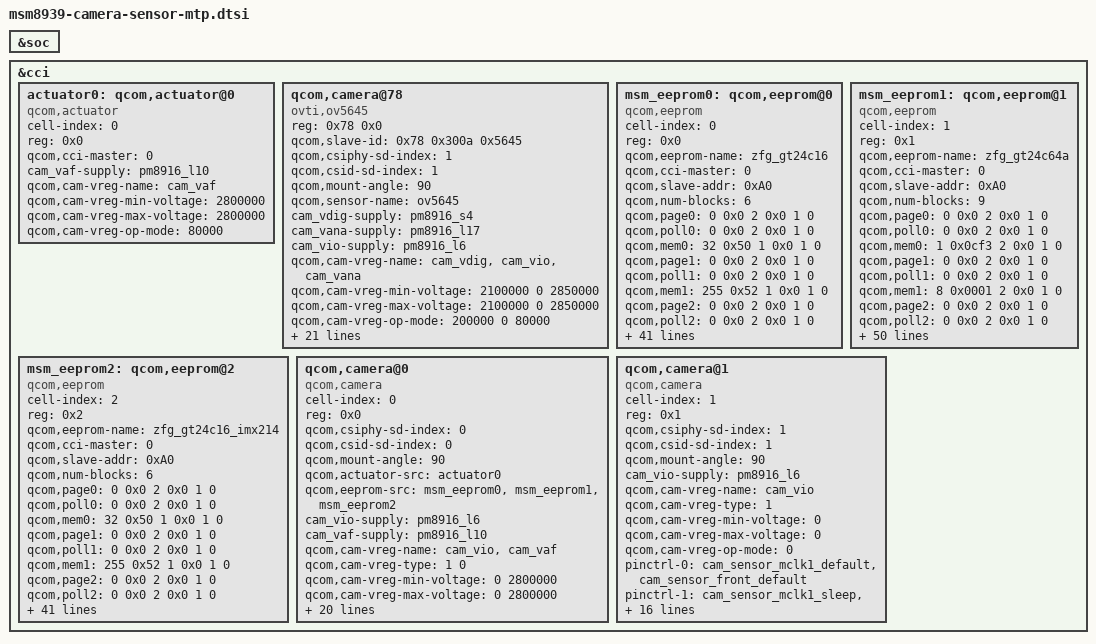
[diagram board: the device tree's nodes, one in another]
/*
 * Copyright (c) 2014-2015, The Linux Foundation. All rights reserved.
 *
 * This program is free software; you can redistribute it and/or modify
 * it under the terms of the GNU General Public License version 2 and
 * only version 2 as published by the Free Software Foundation.
 *
 * This program is distributed in the hope that it will be useful,
 * but WITHOUT ANY WARRANTY; without even the implied warranty of
 * MERCHANTABILITY or FITNESS FOR A PARTICULAR PURPOSE.  See the
 * GNU General Public License for more details.
 */

&soc {
};

&cci {

	actuator0: qcom,actuator@0 {
		cell-index = <0>;
		reg = <0x0>;
		compatible = "qcom,actuator";
		qcom,cci-master = <0>;
		cam_vaf-supply = <&pm8916_l10>;
		qcom,cam-vreg-name = "cam_vaf";
		qcom,cam-vreg-min-voltage = <2800000>;
		qcom,cam-vreg-max-voltage = <2800000>;
		qcom,cam-vreg-op-mode = <80000>;
	};

	qcom,camera@78 {
		compatible = "ovti,ov5645";
		reg = <0x78 0x0>;
		qcom,slave-id = <0x78 0x300a 0x5645>;
		qcom,csiphy-sd-index = <1>;
		qcom,csid-sd-index = <1>;
		qcom,mount-angle = <90>;
		qcom,sensor-name = "ov5645";
		cam_vdig-supply = <&pm8916_s4>;
		cam_vana-supply = <&pm8916_l17>;
		cam_vio-supply = <&pm8916_l6>;
		qcom,cam-vreg-name = "cam_vdig", "cam_vio", "cam_vana";
		qcom,cam-vreg-min-voltage = <2100000 0 2850000>;
		qcom,cam-vreg-max-voltage = <2100000 0 2850000>;
		qcom,cam-vreg-op-mode = <200000 0 80000>;
		pinctrl-names = "cam_default", "cam_suspend";
		pinctrl-0 = <&cam_sensor_mclk1_default
				&cam_sensor_front_default>;
		pinctrl-1 = <&cam_sensor_mclk1_sleep &cam_sensor_front_sleep>;
		gpios = <&msm_gpio 27 0>,
			<&msm_gpio 28 0>,
			<&msm_gpio 33 0>;
		qcom,gpio-reset = <1>;
		qcom,gpio-standby = <2>;
		qcom,gpio-req-tbl-num = <0 1 2>;
		qcom,gpio-req-tbl-flags = <1 0 0>;
		qcom,gpio-req-tbl-label = "CAMIF_MCLK",
					"CAM_RESET",
					"CAM_STANDBY";
		qcom,gpio-set-tbl-num = <1 1>;
		qcom,gpio-set-tbl-flags = <0 2>;
		qcom,gpio-set-tbl-delay = <1000 4000>;
		qcom,csi-lane-assign = <0x4320>;
		qcom,csi-lane-mask = <0x3>;
		qcom,sensor-position = <1>;
		qcom,sensor-mode = <0>;
		qcom,cci-master = <0>;
		clocks = <&clock_gcc clk_mclk1_clk_src>,
				<&clock_gcc clk_gcc_camss_mclk1_clk>;
		clock-names = "cam_src_clk", "cam_clk";
	};

 msm_eeprom0: qcom,eeprom@0 {
		cell-index = <0>;
		reg = <0x0>;
		qcom,eeprom-name = "zfg_gt24c16";
		compatible = "qcom,eeprom";
		qcom,cci-master = <0>;
			
		qcom,slave-addr = <0xA0>;		
		qcom,num-blocks = <6>;
		
		qcom,page0 = <0 0x0 2 0x0 1 0>;
		qcom,poll0 = <0 0x0 2 0x0 1 0>;
		qcom,mem0 = <32 0x50 1 0x0 1 0>;  

		qcom,page1 = <0 0x0 2 0x0 1 0>;
		qcom,poll1 = <0 0x0 2 0x0 1 0>;
		qcom,mem1 = <255 0x52 1 0x0 1 0>;  

		qcom,page2 = <0 0x0 2 0x0 1 0>;
		qcom,poll2 = <0 0x0 2 0x0 1 0>;
		qcom,mem2 = <255 0x53 1 0x0 1 0>;  
		
		qcom,page3 = <0 0x0 2 0x0 1 0>;
		qcom,poll3 = <0 0x0 2 0x0 1 0>;
		qcom,mem3 = <255 0x54 1 0x0 1 0>;  
		
		qcom,page4 = <0 0x0 2 0x0 1 0>;
		qcom,poll4 = <0 0x0 2 0x0 1 0>;
		qcom,mem4 = <255 0x55 1 0x0 1 0>;  
		
		qcom,page5 = <0 0x0 2 0x0 1 0>;
		qcom,poll5 = <0 0x0 2 0x0 1 0>;
		qcom,mem5 = <86 0x56 1 0x0 1 0>; 
		
		cam_vio-supply = <&pm8916_l6>; 
	    qcom,cam-vreg-name =  "cam_vio";
		qcom,cam-vreg-min-voltage = <0 >;
		qcom,cam-vreg-max-voltage = <0>;
		qcom,cam-vreg-op-mode = <0>;
		pinctrl-names = "cam_default", "cam_suspend";
		pinctrl-0 = <&cam_sensor_mclk0_default &cam_sensor_rear_default>;
		pinctrl-1 = <&cam_sensor_mclk0_sleep &cam_sensor_rear_sleep>;
		qcom,gpio-no-mux = <0>;
		gpios = <&msm_gpio 26 0>,
			<&msm_gpio 35 0>,
			<&msm_gpio 34 0>,
			<&msm_gpio 109 0>,
			<&msm_gpio 69 0>;
		qcom,gpio-reset = <1>;
		qcom,gpio-standby = <2>;
		qcom,gpio-vdig = <3>;
		qcom,gpio-vana = <4>;
		qcom,gpio-req-tbl-num = <0 1 2 3 4>;
		qcom,gpio-req-tbl-flags = <1 0 0 0 0>;
		qcom,gpio-req-tbl-label = "CAMIF_MCLK0",
			"CAM_RESET0",
			"CAM_STANDBY0",
				"CAM_VDIG",
			"CAM_VANA";
		qcom,gpio-set-tbl-num = <1 1>;
		qcom,gpio-set-tbl-flags = <0 2>;
		qcom,gpio-set-tbl-delay = <1000 4000>;
		qcom,cam-power-seq-type =  "sensor_vreg","sensor_gpio", "sensor_clk";
		qcom,cam-power-seq-val = "cam_vio", "sensor_gpio_vaf", "sensor_cam_mclk";
		qcom,cam-power-seq-cfg-val = <1 1 24000000>;
		qcom,cam-power-seq-delay = <10 30 5>;
		clocks = <&clock_gcc clk_mclk0_clk_src>,
				<&clock_gcc clk_gcc_camss_mclk0_clk>;
		clock-names = "cam_src_clk", "cam_clk";
	};

    msm_eeprom1: qcom,eeprom@1 {
		cell-index = <1>;
		reg = <0x1>;
		qcom,eeprom-name = "zfg_gt24c64a";
		compatible = "qcom,eeprom";
		qcom,cci-master = <0>;
			
		qcom,slave-addr = <0xA0>;		
		qcom,num-blocks = <9>;
		
		qcom,page0 = <0 0x0 2 0x0 1 0>;
		qcom,poll0 = <0 0x0 2 0x0 1 0>;
		qcom,mem0 = <1 0x0cf3 2 0x0 1 0>;  //AWB flag

		qcom,page1 = <0 0x0 2 0x0 1 0>;
		qcom,poll1 = <0 0x0 2 0x0 1 0>;
		qcom,mem1 = <8 0x0001 2 0x0 1 0>;  //Module info(include checksum)

		qcom,page2 = <0 0x0 2 0x0 1 0>;
		qcom,poll2 = <0 0x0 2 0x0 1 0>;
		qcom,mem2 = <13 0x0CF4 2 0x0 1 0>;  //AWB(include checksum)
		
		qcom,page3 = <0 0x0 2 0x0 1 0>;
		qcom,poll3 = <0 0x0 2 0x0 1 0>;
		qcom,mem3 = <1770 0x0D01 2 0x0 1 0>;  //LSC(include flag and checksum)
		
		qcom,page4 = <0 0x0 2 0x0 1 0>;
		qcom,poll4 = <0 0x0 2 0x0 1 0>;
		qcom,mem4 = <8 0x0CE6 2 0x0 1 0>;  //AF(include flag and checksum)
		
		qcom,page5 = <0 0x0 2 0x0 1 0>;
		qcom,poll5 = <0 0x0 2 0x0 1 0>;
		qcom,mem5 = <7 0x13EB 2 0x0 1 0>;  //PD GAIN(include flag)
		
		qcom,page6 = <0 0x0 2 0x0 1 0>;
		qcom,poll6 = <0 0x0 2 0x0 1 0>;
		qcom,mem6 = <262 0x13F2 2 0x0 1 0>;  //PD LEFT GAIN MAP
		
		qcom,page7 = <0 0x0 2 0x0 1 0>;
		qcom,poll7 = <0 0x0 2 0x0 1 0>;
		qcom,mem7 = <263 0x14F8 2 0x0 1 0>;  //PD RIGHT GAIN MAP(include checksum)
		
		qcom,page8 = <0 0x0 2 0x0 1 0>;
		qcom,poll8 = <0 0x0 2 0x0 1 0>;
		qcom,mem8 = <3 0x17F3 2 0x0 1 0>;  //PD CC(include flag)
		
		cam_vio-supply = <&pm8916_l6>; 
	        qcom,cam-vreg-name =  "cam_vio";
		qcom,cam-vreg-min-voltage = <0 >;
		qcom,cam-vreg-max-voltage = <0>;
		qcom,cam-vreg-op-mode = <0>;
		pinctrl-names = "cam_default", "cam_suspend";
		pinctrl-0 = <&cam_sensor_mclk0_default &cam_sensor_rear_default>;
		pinctrl-1 = <&cam_sensor_mclk0_sleep &cam_sensor_rear_sleep>;
		qcom,gpio-no-mux = <0>;
		gpios = <&msm_gpio 26 0>,
			<&msm_gpio 35 0>,
			<&msm_gpio 34 0>,
			<&msm_gpio 109 0>,
			<&msm_gpio 69 0>;
		qcom,gpio-reset = <1>;
		qcom,gpio-standby = <2>;
		qcom,gpio-vdig = <3>;
		qcom,gpio-vana = <4>;
		qcom,gpio-req-tbl-num = <0 1 2 3 4>;
		qcom,gpio-req-tbl-flags = <1 0 0 0 0>;
		qcom,gpio-req-tbl-label = "CAMIF_MCLK0",
			"CAM_RESET0",
			"CAM_STANDBY0",
				"CAM_VDIG",
			"CAM_VANA";
		qcom,gpio-set-tbl-num = <1 1>;
		qcom,gpio-set-tbl-flags = <0 2>;
		qcom,gpio-set-tbl-delay = <1000 4000>;
		qcom,cam-power-seq-type =  "sensor_vreg","sensor_gpio", "sensor_clk";
		qcom,cam-power-seq-val = "cam_vio", "sensor_gpio_vaf", "sensor_cam_mclk";
		qcom,cam-power-seq-cfg-val = <1 1 24000000>;
		qcom,cam-power-seq-delay = <10 30 5>;
		clocks = <&clock_gcc clk_mclk0_clk_src>,
				<&clock_gcc clk_gcc_camss_mclk0_clk>;
		clock-names = "cam_src_clk", "cam_clk";
	};
	
    msm_eeprom2: qcom,eeprom@2 {
		cell-index = <2>;
		reg = <0x2>;
		qcom,eeprom-name = "zfg_gt24c16_imx214";
		compatible = "qcom,eeprom";
		qcom,cci-master = <0>;
			
		qcom,slave-addr = <0xA0>;		
		qcom,num-blocks = <6>;
		
		qcom,page0 = <0 0x0 2 0x0 1 0>;
		qcom,poll0 = <0 0x0 2 0x0 1 0>;
		qcom,mem0 = <32 0x50 1 0x0 1 0>;  

		qcom,page1 = <0 0x0 2 0x0 1 0>;
		qcom,poll1 = <0 0x0 2 0x0 1 0>;
		qcom,mem1 = <255 0x52 1 0x0 1 0>;  

		qcom,page2 = <0 0x0 2 0x0 1 0>;
		qcom,poll2 = <0 0x0 2 0x0 1 0>;
		qcom,mem2 = <255 0x53 1 0x0 1 0>;  
		
		qcom,page3 = <0 0x0 2 0x0 1 0>;
		qcom,poll3 = <0 0x0 2 0x0 1 0>;
		qcom,mem3 = <255 0x54 1 0x0 1 0>;  
		
		qcom,page4 = <0 0x0 2 0x0 1 0>;
		qcom,poll4 = <0 0x0 2 0x0 1 0>;
		qcom,mem4 = <255 0x55 1 0x0 1 0>;  
		
		qcom,page5 = <0 0x0 2 0x0 1 0>;
		qcom,poll5 = <0 0x0 2 0x0 1 0>;
		qcom,mem5 = <86 0x56 1 0x0 1 0>; 
		
		cam_vio-supply = <&pm8916_l6>; 
	    qcom,cam-vreg-name =  "cam_vio";
		qcom,cam-vreg-min-voltage = <0 >;
		qcom,cam-vreg-max-voltage = <0>;
		qcom,cam-vreg-op-mode = <0>;
		pinctrl-names = "cam_default", "cam_suspend";
		pinctrl-0 = <&cam_sensor_mclk0_default &cam_sensor_rear_default>;
		pinctrl-1 = <&cam_sensor_mclk0_sleep &cam_sensor_rear_sleep>;
		qcom,gpio-no-mux = <0>;
		gpios = <&msm_gpio 26 0>,
			<&msm_gpio 35 0>,
			<&msm_gpio 34 0>,
			<&msm_gpio 109 0>,
			<&msm_gpio 69 0>;
		qcom,gpio-reset = <1>;
		qcom,gpio-standby = <2>;
		qcom,gpio-vdig = <3>;
		qcom,gpio-vana = <4>;
		qcom,gpio-req-tbl-num = <0 1 2 3 4>;
		qcom,gpio-req-tbl-flags = <1 0 0 0 0>;
		qcom,gpio-req-tbl-label = "CAMIF_MCLK0",
			"CAM_RESET0",
			"CAM_STANDBY0",
				"CAM_VDIG",
			"CAM_VANA";
		qcom,gpio-set-tbl-num = <1 1>;
		qcom,gpio-set-tbl-flags = <0 2>;
		qcom,gpio-set-tbl-delay = <1000 4000>;
		qcom,cam-power-seq-type =  "sensor_vreg","sensor_gpio", "sensor_clk";
		qcom,cam-power-seq-val = "cam_vio", "sensor_gpio_vaf", "sensor_cam_mclk";
		qcom,cam-power-seq-cfg-val = <1 1 24000000>;
		qcom,cam-power-seq-delay = <10 30 5>;
		clocks = <&clock_gcc clk_mclk0_clk_src>,
				<&clock_gcc clk_gcc_camss_mclk0_clk>;
		clock-names = "cam_src_clk", "cam_clk";
	};

	qcom,camera@0 {
		cell-index = <0>;
		compatible = "qcom,camera";
		reg = <0x0>;
		qcom,csiphy-sd-index = <0>;
		qcom,csid-sd-index = <0>;
		qcom,mount-angle = <90>;
		qcom,actuator-src = <&actuator0>;
		qcom,eeprom-src = <&msm_eeprom0 &msm_eeprom1 &msm_eeprom2>;
		cam_vio-supply = <&pm8916_l6>;
		cam_vaf-supply = <&pm8916_l10>;
		qcom,cam-vreg-name = "cam_vio", "cam_vaf";
		qcom,cam-vreg-type = <1 0>;
		qcom,cam-vreg-min-voltage = <0 2800000>;
		qcom,cam-vreg-max-voltage = <0 2800000>;
		qcom,cam-vreg-op-mode = <0 100000>;
		pinctrl-names = "cam_default", "cam_suspend";
		pinctrl-0 = <&cam_sensor_mclk0_default &cam_sensor_rear_default>;
		pinctrl-1 = <&cam_sensor_mclk0_sleep &cam_sensor_rear_sleep>;
		gpios = <&msm_gpio 26 0>,
			<&msm_gpio 35 0>,
			<&msm_gpio 34 0>,
			<&msm_gpio 109 0>,
			<&msm_gpio 69 0>;
		qcom,gpio-reset = <1>;
		qcom,gpio-standby = <2>;
		qcom,gpio-vdig = <3>;
		qcom,gpio-vana = <4>;
		qcom,gpio-req-tbl-num = <0 1 2 3 4>;
		qcom,gpio-req-tbl-flags = <1 0 0 0 0>;
		qcom,gpio-req-tbl-label = "CAMIF_MCLK0",
			"CAM_RESET0",
			"CAM_STANDBY0",
			"CAM_VDIG",
			"CAM_VANA";
		qcom,sensor-position = <0>;
		qcom,sensor-mode = <0>;
		qcom,cci-master = <0>;
		status = "ok";
		clocks = <&clock_gcc clk_mclk0_clk_src>,
				<&clock_gcc clk_gcc_camss_mclk0_clk>;
		clock-names = "cam_src_clk", "cam_clk";
	};

	qcom,camera@1 {
		cell-index = <1>;
		compatible = "qcom,camera";
		reg = <0x1>;
		qcom,csiphy-sd-index = <1>;
		qcom,csid-sd-index = <1>;
		qcom,mount-angle = <90>;
		cam_vio-supply = <&pm8916_l6>;
		qcom,cam-vreg-name =  "cam_vio";
		qcom,cam-vreg-type = <1>;
		qcom,cam-vreg-min-voltage = <0>;
		qcom,cam-vreg-max-voltage = <0>;
		qcom,cam-vreg-op-mode = <0>;
		pinctrl-names = "cam_default", "cam_suspend";
		pinctrl-0 = <&cam_sensor_mclk1_default &cam_sensor_front_default>;
		pinctrl-1 = <&cam_sensor_mclk1_sleep &cam_sensor_front_sleep>;
		gpios = <&msm_gpio 27 0>,
			<&msm_gpio 28 0>,
			<&msm_gpio 33 0>,
			<&msm_gpio 17 0>,
			<&msm_gpio 69 0>;
		qcom,gpio-reset = <1>;
		qcom,gpio-standby = <2>;
		qcom,gpio-vdig = <3>;
		qcom,gpio-vana = <4>;
		qcom,gpio-req-tbl-num = <0 1 2 3 4>;
		qcom,gpio-req-tbl-flags = <1 0 0 0 0>;
		qcom,gpio-req-tbl-label = "CAMIF_MCLK1",
			"CAM_RESET1",
			"CAM_STANDBY1",
			"CAM_VDIG",
			"CAM_VANA";
		qcom,sensor-position = <1>;
		qcom,sensor-mode = <0>;
		qcom,cci-master = <0>;
		status = "ok";
		clocks = <&clock_gcc clk_mclk1_clk_src>,
				<&clock_gcc clk_gcc_camss_mclk1_clk>;
		clock-names = "cam_src_clk", "cam_clk";
	};
};
